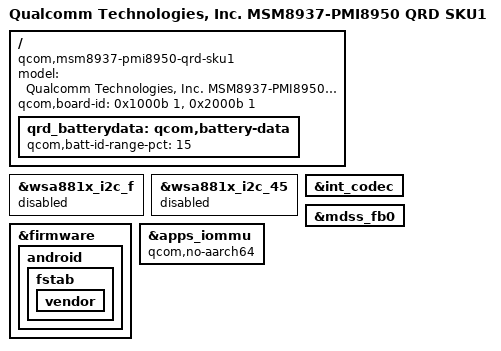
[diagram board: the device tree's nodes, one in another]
/*
 * Copyright (c) 2015-2016, The Linux Foundation. All rights reserved.
 *
 * This program is free software; you can redistribute it and/or modify
 * it under the terms of the GNU General Public License version 2 and
 * only version 2 as published by the Free Software Foundation.
 *
 * This program is distributed in the hope that it will be useful,
 * but WITHOUT ANY WARRANTY; without even the implied warranty of
 * MERCHANTABILITY or FITNESS FOR A PARTICULAR PURPOSE.  See the
 * GNU General Public License for more details.
 */

/dts-v1/;

#include "../qcom/msm8937.dtsi"
#include "../qcom/pmi8950.dtsi"
#include "../qcom/msm8937-qrd.dtsi"
#include "../qcom/msm8937-mdss-panels.dtsi"
#include "common/msm8937-common.dtsi"
#include "land/msm8937-land.dtsi"

/ {
	model = "Qualcomm Technologies, Inc. MSM8937-PMI8950 QRD SKU1";
	compatible = "qcom,msm8937-pmi8950-qrd-sku1",
		   "qcom,msm8937-qrd", "qcom,msm8937", "qcom,qrd";
	qcom,board-id= <0x1000b 1>, <0x2000b 1>;
};

/ {
	qrd_batterydata: qcom,battery-data {
		qcom,batt-id-range-pct = <15>;
		#include "land/batterydata-qrd-Desay-4v4-4000mah.dtsi"
		#include "land/batterydata-qrd-Atl-4v4-4000mah.dtsi"
		#include "land/batterydata-qrd-Coslight-4v4-4000mah.dtsi"
		#include "land/batterydata-qrd-feimaotui-4v4-4000mah.dtsi"
	};
};

&wsa881x_i2c_f {
	status = "disabled";
};

&wsa881x_i2c_45 {
	status = "disabled";
};

&int_codec {
		/delete-property/ asoc-wsa-codec-names;
		/delete-property/ asoc-wsa-codec-prefixes;
		/delete-property/ msm-vdd-wsa-switch-supply;
		/delete-property/ qcom,msm-vdd-wsa-switch-voltage;
		/delete-property/ qcom,msm-vdd-wsa-switch-current;
		/delete-property/ qcom,msm-gpios;
		/delete-property/ qcom,pinctrl-names;
		/delete-property/ pinctrl-names;
		/delete-property/ pinctrl-0;
		/delete-property/ pinctrl-1;
};

&mdss_fb0 { /delete-node/ qcom,cont-splash-memory;};

&firmware {
	android {
		fstab {
			vendor {
                		status = "ok";
			};
		};
	};
};

&apps_iommu {
	qcom,no-aarch64;
};
